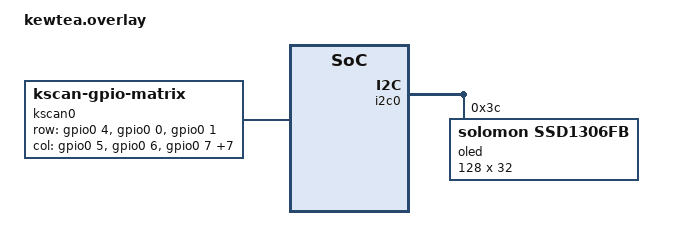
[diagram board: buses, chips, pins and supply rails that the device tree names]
/*
 * kewtea.overlay
 *
 * Device-tree overlay for the kewtea 30% ortholinear keyboard shield.
 * Targets the nice_nano_v2 board (Pro Micro NRF52840 compatible).
 *
 * Matrix wiring  — all pins are on gpio0 (P0.xx):
 *   ROW0 = P0.04 | ROW1 = P0.00 | ROW2 = P0.01
 *   COL0..COL5  = P0.05–P0.10
 *   COL6..COL9  = P0.13–P0.16
 *
 * Note: P0.00 and P0.01 double as the 32.768 kHz LFXO pads on bare NRF52840
 * silicon. They are safe to use as GPIO here because BLE is disabled and no
 * external crystal is fitted on this board.
 *
 * OLED wiring (physical header pins, I2C0):
 *   SDA = P0.17 (header pin 5) | SCL = P0.20 (header pin 6)
 */

#include <dt-bindings/gpio/gpio.h>

/ {
    chosen {
        zmk,kscan   = &kscan0;
        zmk,display = &oled;
    };

    /**
     * @brief GPIO matrix keyboard scanner.
     *
     * Diode direction is row2col: row pins are driven HIGH one at a time,
     * column pins are sampled as inputs with pull-down resistors.
     * Flip to "col2row" here if keys register inverted after assembly.
     */
    kscan0: kscan {
        compatible = "zmk,kscan-gpio-matrix";
        diode-direction = "row2col";

        row-gpios
            = <&gpio0  4 GPIO_ACTIVE_HIGH>   /* ROW0 — Q..P */
            , <&gpio0  0 GPIO_ACTIVE_HIGH>   /* ROW1 — A..SEMI */
            , <&gpio0  1 GPIO_ACTIVE_HIGH>   /* ROW2 — Z..DOT */
            ;

        col-gpios
            = <&gpio0  5 (GPIO_ACTIVE_HIGH | GPIO_PULL_DOWN)>   /* COL0 */
            , <&gpio0  6 (GPIO_ACTIVE_HIGH | GPIO_PULL_DOWN)>   /* COL1 */
            , <&gpio0  7 (GPIO_ACTIVE_HIGH | GPIO_PULL_DOWN)>   /* COL2 */
            , <&gpio0  8 (GPIO_ACTIVE_HIGH | GPIO_PULL_DOWN)>   /* COL3 */
            , <&gpio0  9 (GPIO_ACTIVE_HIGH | GPIO_PULL_DOWN)>   /* COL4 */
            , <&gpio0 10 (GPIO_ACTIVE_HIGH | GPIO_PULL_DOWN)>   /* COL5 */
            , <&gpio0 13 (GPIO_ACTIVE_HIGH | GPIO_PULL_DOWN)>   /* COL6 */
            , <&gpio0 14 (GPIO_ACTIVE_HIGH | GPIO_PULL_DOWN)>   /* COL7 */
            , <&gpio0 15 (GPIO_ACTIVE_HIGH | GPIO_PULL_DOWN)>   /* COL8 */
            , <&gpio0 16 (GPIO_ACTIVE_HIGH | GPIO_PULL_DOWN)>   /* COL9 */
            ;
    };
};

/**
 * @brief I2C0 bus — hosts the SSD1306 OLED display.
 *
 * Pin assignment matches the nice_nano_v2 board definition:
 *   SDA = P0.17, SCL = P0.20.
 * The board DTS already declares pinctrl for i2c0; this node
 * enables the bus and attaches the display device.
 */
&i2c0 {
    status = "okay";

    /**
     * @brief Solomon SSD1306 — 128×32 monochrome OLED, I2C address 0x3C.
     *
     * Parameters are set for a standard 128×32 panel:
     *   - multiplex-ratio 31  (MUX = display height − 1)
     *   - com-sequential      (sequential COM pin configuration for 32-row panels)
     *   - segment-remap       (column address 127 maps to SEG0)
     *   - com-invdir          (scan from COM[N−1] to COM0 for correct orientation)
     */
    oled: ssd1306@3c {
        compatible = "solomon,ssd1306fb";
        reg = <0x3c>;
        width = <128>;
        height = <32>;
        segment-offset = <0>;
        page-offset = <0>;
        display-offset = <0>;
        multiplex-ratio = <31>;
        prechargep = <0x22>;
        segment-remap;
        com-invdir;
        com-sequential;
    };
};
